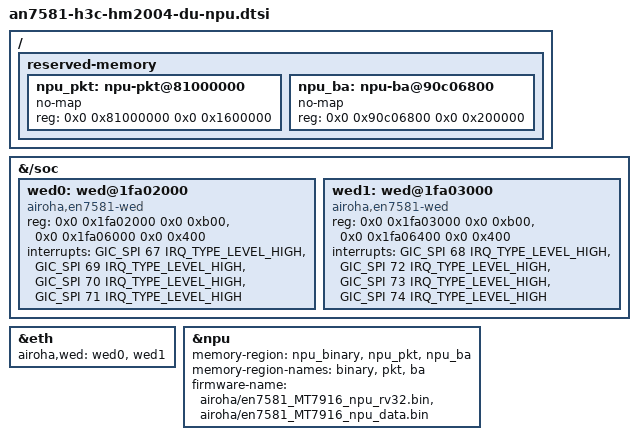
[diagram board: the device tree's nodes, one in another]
// SPDX-License-Identifier: (GPL-2.0-only OR BSD-2-Clause)
/*
 * H3C HM2004-DU —— AN7581 WED v1 + NPU 保留内存叠加层
 *
 * 为什么这些节点必须由本文件提供，而不是内核补丁：
 *   wed0/wed1、wdma 在参考实现里是直接改 target/linux/airoha/dts/an7581.dtsi，
 *   那是 OpenWrt 的 target 目录，不在内核源码树里；我们注入的 990-01/990-02/991
 *   只能改内核源码，够不到这个文件。第一次构建出来的镜像里 FDT 完全没有
 *   wed@1fa0* 节点、eth 也没有 airoha,wed —— 就是因为漏了这一层。
 *
 * 驱动侧的实际要求（读 airoha_wed.c 得出，不是猜的）：
 *   compatible  "airoha,en7581-wed", "syscon"   → airoha_wed_of_match + syscon_node_to_regmap
 *   reg[0]      WED 寄存器区                     → syscon_node_to_regmap(np)
 *   reg[1]      WDMA 寄存器区                    → of_iomap(np, 1) / of_address_to_resource(np, 1)
 *   interrupts[0] 平台中断                        → platform_get_irq(pdev, 0)
 *   后面几个中断驱动并不读，保留只为与参考实现一致、便于日后调试。
 *   节点必须是 /soc（simple-bus）下的子节点，否则 of_find_device_by_node() 拿不到 pdev。
 *   PCIe 基址不由 DTS 提供：驱动内 en7581_wed_data.pcie_base = {0x1fc00000, 0x1fc20000}，
 *   按 index 取，所以 <&wed0>, <&wed1> 的顺序不能颠倒。
 */

/ {
	reserved-memory {
		#address-cells = <2>;
		#size-cells = <2>;
		ranges;

		npu_pkt: npu-pkt@81000000 {
			no-map;
			reg = <0x0 0x81000000 0x0 0x1600000>;
		};

		npu_ba: npu-ba@90c06800 {
			no-map;
			reg = <0x0 0x90c06800 0x0 0x200000>;
		};
	};
};

/* soc 节点在基座 dtsi 里没有标签，只能按路径引用 */
&{/soc} {
	wed0: wed@1fa02000 {
		compatible = "airoha,en7581-wed", "syscon";
		reg = <0x0 0x1fa02000 0x0 0xb00>,
		      <0x0 0x1fa06000 0x0 0x400>;
		reg-names = "wed", "wdma";
		interrupts = <GIC_SPI 67 IRQ_TYPE_LEVEL_HIGH>,
			     <GIC_SPI 69 IRQ_TYPE_LEVEL_HIGH>,
			     <GIC_SPI 70 IRQ_TYPE_LEVEL_HIGH>,
			     <GIC_SPI 71 IRQ_TYPE_LEVEL_HIGH>;
		interrupt-names = "wed", "wdma-port0",
				  "wdma-port1", "wdma-woe";
	};

	wed1: wed@1fa03000 {
		compatible = "airoha,en7581-wed", "syscon";
		reg = <0x0 0x1fa03000 0x0 0xb00>,
		      <0x0 0x1fa06400 0x0 0x400>;
		reg-names = "wed", "wdma";
		interrupts = <GIC_SPI 68 IRQ_TYPE_LEVEL_HIGH>,
			     <GIC_SPI 72 IRQ_TYPE_LEVEL_HIGH>,
			     <GIC_SPI 73 IRQ_TYPE_LEVEL_HIGH>,
			     <GIC_SPI 74 IRQ_TYPE_LEVEL_HIGH>;
		interrupt-names = "wed", "wdma-port0",
				  "wdma-port1", "wdma-woe";
	};
};

/* 顺序即 index：airoha_eth.c 用 of_parse_phandle(..., "airoha,wed", i) 逐个取 */
&eth {
	airoha,wed = <&wed0>, <&wed1>;
};

&npu {
	status = "okay";

	memory-region = <&npu_binary>, <&npu_pkt>, <&npu_ba>;
	memory-region-names = "binary", "pkt", "ba";

	/* 厂商 98K 固件（files/lib/firmware/airoha/ 随镜像打包） */
	firmware-name = "airoha/en7581_MT7916_npu_rv32.bin",
			"airoha/en7581_MT7916_npu_data.bin";
};
